AUTOSAR XML (schema 00044)
package /RUNNABLES_LAB
  sender receiver interface SR_DataInputs
    data VAL1: type=uint16
    data VAL2: type=uint16
  sender receiver interface SR_SumResults
    data SumResults: type=uint32
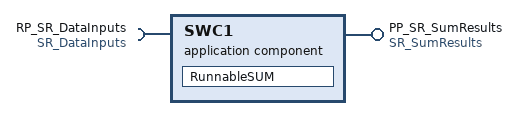
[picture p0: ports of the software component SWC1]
  application sw component type SWC1
    require port RP_SR_DataInputs: required-interface=SR_DataInputs
    provide port PP_SR_SumResults: provided-interface=SR_SumResults
    behavior SWC1_InternalBehavior
      runnable RunnableSUM: symbol=SUM
        data-read-access:
          access Data_VAL1: accessed-variable=RP_SR_DataInputs.VAL1
          access Data_VAL2: accessed-variable=RP_SR_DataInputs.VAL2
        data-write-access:
          access Data_SumResults: accessed-variable=PP_SR_SumResults.SumResults
